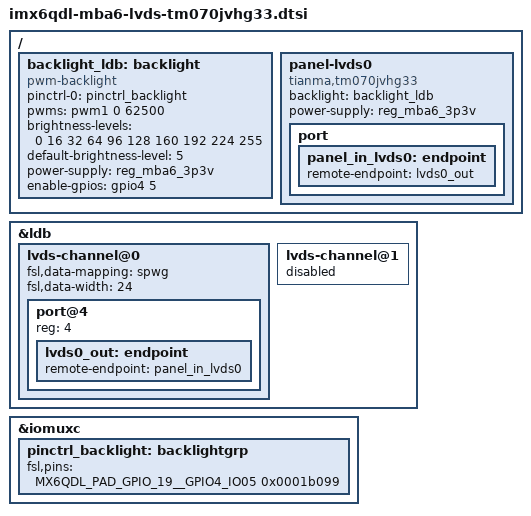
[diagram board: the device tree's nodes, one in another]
// SPDX-License-Identifier: (GPL-2.0-or-later OR MIT)
/*
 * Copyright 2018 TQ Systems GmbH
 * Author: Markus Niebel <Markus.Niebel@tq-group.com>
 */

/ {
	backlight_ldb: backlight {
		compatible = "pwm-backlight";
		pinctrl-names = "default";
		pinctrl-0 = <&pinctrl_backlight>;
		pwms = <&pwm1 0 62500>;
		brightness-levels = <0 16 32 64 96 128 160 192 224 255>;
		default-brightness-level = <5>;
		power-supply = <&reg_mba6_3p3v>;
		enable-gpios = <&gpio4 5 GPIO_ACTIVE_HIGH>;
		status = "okay";
	};

	panel-lvds0 {
		compatible = "tianma,tm070jvhg33";
		backlight = <&backlight_ldb>;
		power-supply = <&reg_mba6_3p3v>;
		status = "okay";

		port {
			panel_in_lvds0: endpoint {
				remote-endpoint = <&lvds0_out>;
			};
		};
	};
};

&ldb {
	status = "okay";

	lvds-channel@0 {
		fsl,data-mapping = "spwg";
		fsl,data-width = <24>;
		status = "okay";

		port@4 {
			reg = <4>;

			lvds0_out: endpoint {
				remote-endpoint = <&panel_in_lvds0>;
			};
		};
	};

	lvds-channel@1 {
		status = "disabled";
	};
};

&iomuxc {
	pinctrl_backlight: backlightgrp {
		fsl,pins = <
			/* LCD.BLT_EN */
			MX6QDL_PAD_GPIO_19__GPIO4_IO05 0x0001b099
		>;
	};
};
